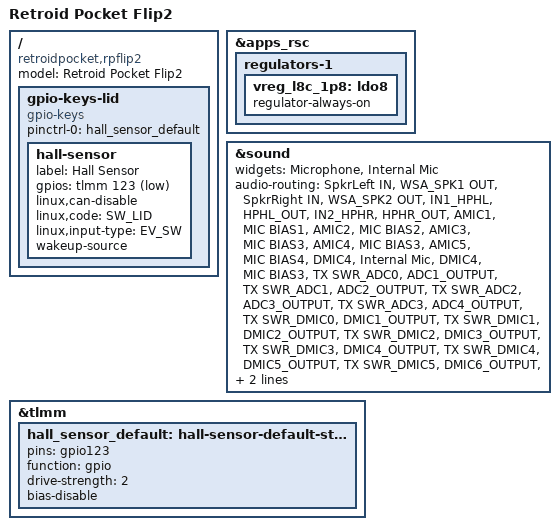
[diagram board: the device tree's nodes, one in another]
// SPDX-License-Identifier: GPL-2.0
/*
 * Copyright (c) 2025, ROCKNIX <https://rocknix.org>.
 */

/dts-v1/;

#include <dt-bindings/input/gpio-keys.h>
#include "sm8250-retroidpocket-rp5.dts"

/ {
	model = "Retroid Pocket Flip2";
	compatible = "retroidpocket,rpflip2", "qcom,sm8250";

	gpio-keys-lid {
		compatible = "gpio-keys";
		pinctrl-names = "default";
		pinctrl-0 = <&hall_sensor_default>;

		hall-sensor {
			label = "Hall Sensor";
			gpios = <&tlmm 123 GPIO_ACTIVE_LOW>;
			linux,can-disable;
			linux,code = <SW_LID>;
			linux,input-type = <EV_SW>;
			wakeup-source;
		};
	};
};

&apps_rsc {
	regulators-1 {
		vreg_l8c_1p8: ldo8 {
			regulator-always-on;
		};
	};
};

&sound {
	widgets =
		"Microphone", "Internal Mic";
	audio-routing =
		"SpkrLeft IN", "WSA_SPK1 OUT",
		"SpkrRight IN", "WSA_SPK2 OUT",
		"IN1_HPHL", "HPHL_OUT",
		"IN2_HPHR", "HPHR_OUT",
		"AMIC1", "MIC BIAS1",
		"AMIC2", "MIC BIAS2",
		"AMIC3", "MIC BIAS3",
		"AMIC4", "MIC BIAS3",
		"AMIC5", "MIC BIAS4",
		"DMIC4", "Internal Mic",
		"DMIC4", "MIC BIAS3",
		"TX SWR_ADC0", "ADC1_OUTPUT",
		"TX SWR_ADC1", "ADC2_OUTPUT",
		"TX SWR_ADC2", "ADC3_OUTPUT",
		"TX SWR_ADC3", "ADC4_OUTPUT",
		"TX SWR_DMIC0", "DMIC1_OUTPUT",
		"TX SWR_DMIC1", "DMIC2_OUTPUT",
		"TX SWR_DMIC2", "DMIC3_OUTPUT",
		"TX SWR_DMIC3", "DMIC4_OUTPUT",
		"TX SWR_DMIC4", "DMIC5_OUTPUT",
		"TX SWR_DMIC5", "DMIC6_OUTPUT",
		"TX SWR_DMIC6", "DMIC7_OUTPUT",
		"TX SWR_DMIC7", "DMIC8_OUTPUT";
};

&tlmm {
	hall_sensor_default: hall-sensor-default-state {
		pins = "gpio123";
		function = "gpio";
		drive-strength = <2>;
		bias-disable;
	};
};
